AUTOSAR XML (schema 4-0-3)
standard types defined: Boolean
package /AUTOSAR_Platform/DataConstrs
  range DC_Boolean: raw 0..1
package /PATAC/MSM/ComponentTypes
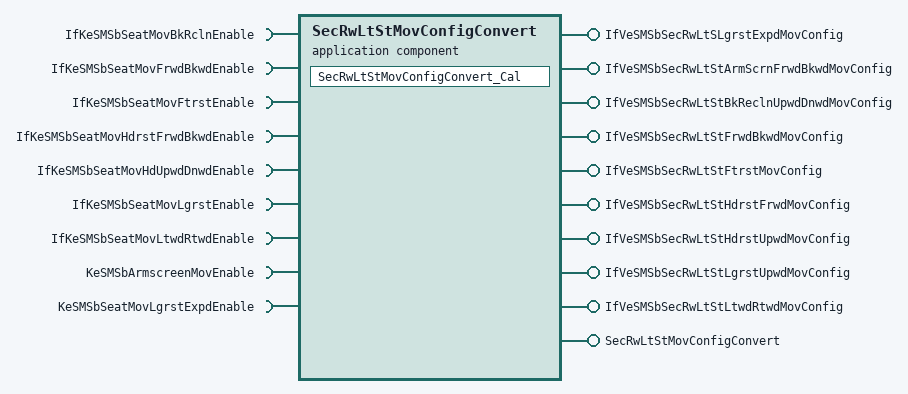
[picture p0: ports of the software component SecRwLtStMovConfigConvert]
  application sw component type SecRwLtStMovConfigConvert
    10 x provide port:
      IfVeSMSbSecRwLtSLgrstExpdMovConfig: nonqueued-sender-com-spec{data-element=IfVeSMSbSecRwLtSLgrstExpdMovConfig/Val, init-value=0}, provided-interface=IfVeSMSbSecRwLtSLgrstExpdMovConfig
      IfVeSMSbSecRwLtStArmScrnFrwdBkwdMovConfig: nonqueued-sender-com-spec{data-element=IfVeSMSbSecRwLtStArmScrnFrwdBkwdMovConfig/Val, init-value=0}, provided-interface=IfVeSMSbSecRwLtStArmScrnFrwdBkwdMovConfig
      IfVeSMSbSecRwLtStBkReclnUpwdDnwdMovConfig: nonqueued-sender-com-spec{data-element=IfVeSMSbSecRwLtStBkReclnUpwdDnwdMovConfig/Val, init-value=0}, provided-interface=IfVeSMSbSecRwLtStBkReclnUpwdDnwdMovConfig
      IfVeSMSbSecRwLtStFrwdBkwdMovConfig: nonqueued-sender-com-spec{data-element=IfVeSMSbSecRwLtStFrwdBkwdMovConfig/Val, init-value=0}, provided-interface=IfVeSMSbSecRwLtStFrwdBkwdMovConfig
      IfVeSMSbSecRwLtStFtrstMovConfig: nonqueued-sender-com-spec{data-element=IfVeSMSbSecRwLtStFtrstMovConfig/Val, init-value=0}, provided-interface=IfVeSMSbSecRwLtStFtrstMovConfig
      IfVeSMSbSecRwLtStHdrstFrwdMovConfig: nonqueued-sender-com-spec{data-element=IfVeSMSbSecRwLtStHdrstFrwdMovConfig/Val, init-value=0}, provided-interface=IfVeSMSbSecRwLtStHdrstFrwdMovConfig
      IfVeSMSbSecRwLtStHdrstUpwdMovConfig: nonqueued-sender-com-spec{data-element=IfVeSMSbSecRwLtStHdrstUpwdMovConfig/Val, init-value=0}, provided-interface=IfVeSMSbSecRwLtStHdrstUpwdMovConfig
      IfVeSMSbSecRwLtStLgrstUpwdMovConfig: nonqueued-sender-com-spec{data-element=IfVeSMSbSecRwLtStLgrstUpwdMovConfig/Val, init-value=0}, provided-interface=IfVeSMSbSecRwLtStLgrstUpwdMovConfig
      IfVeSMSbSecRwLtStLtwdRtwdMovConfig: nonqueued-sender-com-spec{data-element=IfVeSMSbSecRwLtStLtwdRtwdMovConfig/Val, init-value=0}, provided-interface=IfVeSMSbSecRwLtStLtwdRtwdMovConfig
      SecRwLtStMovConfigConvert: server-com-spec{operation=Cal, queue-length=1}, provided-interface=SecRwLtStMovConfigConvert
    9 x require port:
      IfKeSMSbSeatMovBkRclnEnable: parameter-require-com-spec{init-value=1, parameter=IfKeSMSbSeatMovBkRclnEnable/Val}, required-interface=IfKeSMSbSeatMovBkRclnEnable
      IfKeSMSbSeatMovFrwdBkwdEnable: parameter-require-com-spec{init-value=1, parameter=IfKeSMSbSeatMovFrwdBkwdEnable/Val}, required-interface=IfKeSMSbSeatMovFrwdBkwdEnable
      IfKeSMSbSeatMovFtrstEnable: parameter-require-com-spec{init-value=1, parameter=IfKeSMSbSeatMovFtrstEnable/Val}, required-interface=IfKeSMSbSeatMovFtrstEnable
      IfKeSMSbSeatMovHdrstFrwdBkwdEnable: parameter-require-com-spec{init-value=1, parameter=IfKeSMSbSeatMovHdrstFrwdBkwdEnable/Val}, required-interface=IfKeSMSbSeatMovHdrstFrwdBkwdEnable
      IfKeSMSbSeatMovHdUpwdDnwdEnable: parameter-require-com-spec{init-value=1, parameter=IfKeSMSbSeatMovHdUpwdDnwdEnable/Val}, required-interface=IfKeSMSbSeatMovHdUpwdDnwdEnable
      IfKeSMSbSeatMovLgrstEnable: parameter-require-com-spec{init-value=1, parameter=IfKeSMSbSeatMovLgrstEnable/Val}, required-interface=IfKeSMSbSeatMovLgrstEnable
      IfKeSMSbSeatMovLtwdRtwdEnable: parameter-require-com-spec{init-value=1, parameter=IfKeSMSbSeatMovLtwdRtwdEnable/Val}, required-interface=IfKeSMSbSeatMovLtwdRtwdEnable
      KeSMSbArmscreenMovEnable: parameter-require-com-spec{init-value=1, parameter=KeSMSbArmscreenMovEnable/Val}, required-interface=KeSMSbArmscreenMovEnable
      KeSMSbSeatMovLgrstExpdEnable: parameter-require-com-spec{init-value=0, parameter=KeSMSbSeatMovLgrstExpdEnable/Val}, required-interface=KeSMSbSeatMovLgrstExpdEnable
    behavior SecRwLtStMovConfigConvert_InternalBehavior
      operation invoked event OIT_SecRwLtStMovConfigConvert_Cal_SecRwLtStMovConfigConvert_Cal: start-on-event=SecRwLtStMovConfigConvert_Cal, operation=SecRwLtStMovConfigConvert.Cal
      runnable SecRwLtStMovConfigConvert_Cal
        data-send-points:
          9 x access:
            SEND_IfVeSMSbSecRwLtSLgrstExpdMovConfig_Val: accessed-variable=IfVeSMSbSecRwLtSLgrstExpdMovConfig.Val
            SEND_IfVeSMSbSecRwLtStArmScrnFrwdBkwdMovConfig_Val: accessed-variable=IfVeSMSbSecRwLtStArmScrnFrwdBkwdMovConfig.Val
            SEND_IfVeSMSbSecRwLtStBkReclnUpwdDnwdMovConfig_Val: accessed-variable=IfVeSMSbSecRwLtStBkReclnUpwdDnwdMovConfig.Val
            SEND_IfVeSMSbSecRwLtStFrwdBkwdMovConfig_Val: accessed-variable=IfVeSMSbSecRwLtStFrwdBkwdMovConfig.Val
            SEND_IfVeSMSbSecRwLtStFtrstMovConfig_Val: accessed-variable=IfVeSMSbSecRwLtStFtrstMovConfig.Val
            SEND_IfVeSMSbSecRwLtStHdrstFrwdMovConfig_Val: accessed-variable=IfVeSMSbSecRwLtStHdrstFrwdMovConfig.Val
            SEND_IfVeSMSbSecRwLtStHdrstUpwdMovConfig_Val: accessed-variable=IfVeSMSbSecRwLtStHdrstUpwdMovConfig.Val
            SEND_IfVeSMSbSecRwLtStLgrstUpwdMovConfig_Val: accessed-variable=IfVeSMSbSecRwLtStLgrstUpwdMovConfig.Val
            SEND_IfVeSMSbSecRwLtStLtwdRtwdMovConfig_Val: accessed-variable=IfVeSMSbSecRwLtStLtwdRtwdMovConfig.Val
        9 x parameter access:
          PA_IfKeSMSbSeatMovBkRclnEnable_Val: accessed-parameter=IfKeSMSbSeatMovBkRclnEnable.Val
          PA_IfKeSMSbSeatMovFrwdBkwdEnable_Val: accessed-parameter=IfKeSMSbSeatMovFrwdBkwdEnable.Val
          PA_IfKeSMSbSeatMovFtrstEnable_Val: accessed-parameter=IfKeSMSbSeatMovFtrstEnable.Val
          PA_IfKeSMSbSeatMovHdrstFrwdBkwdEnable_Val: accessed-parameter=IfKeSMSbSeatMovHdrstFrwdBkwdEnable.Val
          PA_IfKeSMSbSeatMovHdUpwdDnwdEnable_Val: accessed-parameter=IfKeSMSbSeatMovHdUpwdDnwdEnable.Val
          PA_IfKeSMSbSeatMovLgrstEnable_Val: accessed-parameter=IfKeSMSbSeatMovLgrstEnable.Val
          PA_IfKeSMSbSeatMovLtwdRtwdEnable_Val: accessed-parameter=IfKeSMSbSeatMovLtwdRtwdEnable.Val
          PA_KeSMSbArmscreenMovEnable_Val: accessed-parameter=KeSMSbArmscreenMovEnable.Val
          PA_KeSMSbSeatMovLgrstExpdEnable_Val: accessed-parameter=KeSMSbSeatMovLgrstExpdEnable.Val
  swc implementation SecRwLtStMovConfigConvert_Implementation: behavior=SecRwLtStMovConfigConvert_InternalBehavior
    code-descriptors:
      code Default: artifact-descriptors=autosar-engineering-object={short-label=Default, category=SWSRC}
package /PATAC/MSM/ModeAdjust/CalPortInterface
  parameter interface KeSMSbArmscreenMovEnable
    parameter data prototype Val: sw-calibration-access=READ-WRITE, type=Boolean
package /PATAC/MSM/ModeAdjust/PortInterface
  client server interface SecRwLtStMovConfigConvert
    operation Cal
  parameter interface IfKeSMSbSeatMovHdUpwdDnwdEnable
    parameter data prototype Val: sw-calibration-access=READ-WRITE, type=Boolean
  parameter interface KeSMSbSeatMovLgrstExpdEnable
    parameter data prototype Val: sw-calibration-access=READ-WRITE, type=Boolean
  sender receiver interface IfVeSMSbSecRwLtStArmScrnFrwdBkwdMovConfig: invalidation-policy{data-element=IfVeSMSbSecRwLtStArmScrnFrwdBkwdMovConfig/Val, handle-invalid=DONT-INVALIDATE}
    data Val: type=Boolean
  sender receiver interface IfVeSMSbSecRwLtStFtrstMovConfig: invalidation-policy{data-element=IfVeSMSbSecRwLtStFtrstMovConfig/Val, handle-invalid=DONT-INVALIDATE}
    data Val: type=Boolean
  sender receiver interface IfVeSMSbSecRwLtStHdrstFrwdMovConfig: invalidation-policy{data-element=IfVeSMSbSecRwLtStHdrstFrwdMovConfig/Val, handle-invalid=DONT-INVALIDATE}
    data Val: type=Boolean
package /PATAC/MSM/PortInterfaces
  6 x parameter interface:
    IfKeSMSbSeatMovBkRclnEnable
      parameter data prototype Val: sw-calibration-access=READ-WRITE, type=Boolean
    IfKeSMSbSeatMovFrwdBkwdEnable
      parameter data prototype Val: sw-calibration-access=READ-WRITE, type=Boolean
    IfKeSMSbSeatMovFtrstEnable
      parameter data prototype Val: sw-calibration-access=READ-WRITE, type=Boolean
    IfKeSMSbSeatMovHdrstFrwdBkwdEnable
      parameter data prototype Val: sw-calibration-access=READ-WRITE, type=Boolean
    IfKeSMSbSeatMovLgrstEnable
      parameter data prototype Val: sw-calibration-access=READ-WRITE, type=Boolean
    IfKeSMSbSeatMovLtwdRtwdEnable
      parameter data prototype Val: sw-calibration-access=READ-WRITE, type=Boolean
  6 x sender receiver interface:
    IfVeSMSbSecRwLtSLgrstExpdMovConfig: invalidation-policy{data-element=IfVeSMSbSecRwLtSLgrstExpdMovConfig/Val, handle-invalid=DONT-INVALIDATE}
      data Val: type=Boolean
    IfVeSMSbSecRwLtStBkReclnUpwdDnwdMovConfig: invalidation-policy{data-element=IfVeSMSbSecRwLtStBkReclnUpwdDnwdMovConfig/Val, handle-invalid=DONT-INVALIDATE}
      data Val: type=Boolean
    IfVeSMSbSecRwLtStFrwdBkwdMovConfig: invalidation-policy{data-element=IfVeSMSbSecRwLtStFrwdBkwdMovConfig/Val, handle-invalid=DONT-INVALIDATE}
      data Val: type=Boolean
    IfVeSMSbSecRwLtStHdrstUpwdMovConfig: invalidation-policy{data-element=IfVeSMSbSecRwLtStHdrstUpwdMovConfig/Val, handle-invalid=DONT-INVALIDATE}
      data Val: type=Boolean
    IfVeSMSbSecRwLtStLgrstUpwdMovConfig: invalidation-policy{data-element=IfVeSMSbSecRwLtStLgrstUpwdMovConfig/Val, handle-invalid=DONT-INVALIDATE}
      data Val: type=Boolean
    IfVeSMSbSecRwLtStLtwdRtwdMovConfig: invalidation-policy{data-element=IfVeSMSbSecRwLtStLtwdRtwdMovConfig/Val, handle-invalid=DONT-INVALIDATE}
      data Val: type=Boolean
